# ESP32-C5 register map
Vendor: ESPRESSIF SYSTEMS (SHANGHAI) CO., LTD.; Series: ESP32 C-Series; File version: 1
CPU: RV32IMAC r0p0, little endian, no MPU, no FPU, 0 interrupt priority bits
Address unit: 32 bits
Registers are 32-bit, read-write, reset 0x0 unless marked. A register's access mark holds for its fields unless they carry their own. Offsets are from the block's base; [hi:lo] are bit positions; lines under a group give offsets from that group; {n}, {i} and the like mark numbered series.

## MCPWM0 — Motor Control Pulse Width Modulator (MCPWM) Peripheral
Base 0x60014000
0x00 CLK_CFG — PWM clock prescaler register.
  [7:0] CLK_PRESCALE — Configures the prescaler value of clock, so that the period of PWM_clk = 6.25ns * (PWM_CLK_PRESCALE + 1).
{0x4+0x10*i} TIMER{i} (i=0..2) group — Cluster TIMER{i}, containing TIMER?_CFG0, TIMER?_CFG1, TIMER?_SYNC, TIMER?_STATUS
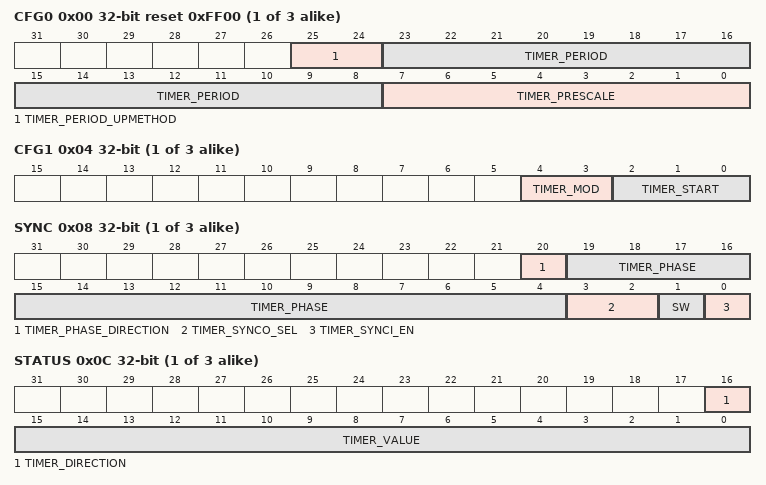
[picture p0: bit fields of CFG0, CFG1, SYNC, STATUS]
  0x00 CFG0 reset 0xFF00 — PWM TIMERx period and update method configuration register.
    [25:24] TIMER_PERIOD_UPMETHOD — Configures the update method for active register of PWM timer%s period.\\0: Immediate\\1: TEZ\\2: Sync\\3: TEZ or sync\\TEZ here and below means timer equal zero event
    [23:8] TIMER_PERIOD — Configures the period shadow of PWM timer%s
    [7:0] TIMER_PRESCALE — Configures the prescaler value of timer%s, so that the period of PT0_clk = Period of PWM_clk * (PWM_TIMER%s_PRESCALE + 1)
  0x04 CFG1 — PWM TIMERx working mode and start/stop control configuration register.
    [4:3] TIMER_MOD — Configures the working mode of PWM timer%s.\\0: Freeze\\1: Increase mode\\2: Decrease mode\\3: Up-down mode
    [2:0] TIMER_START — Configures whether or not to start/stop PWM timer%s.\\0: If PWM timer%s starts, then stops at TEZ\\1: If timer%s starts, then stops at TEP\\2: PWM timer%s starts and runs on\\3: Timer%s starts and stops at the next TEZ\\4: Timer0 starts and stops at the next TEP.\\TEP here and below means the event that happens when the timer equals to period
  0x08 SYNC — PWM TIMERx sync function configuration register.
    [20] TIMER_PHASE_DIRECTION — Configures the PWM timer%s's direction when timer%s mode is up-down mode.\\0: Increase\\1: Decrease
    [19:4] TIMER_PHASE — Configures the phase for timer%s reload on sync event.
    [3:2] TIMER_SYNCO_SEL — Configures the selection of PWM timer%s sync_out.\\0: Sync_in\\1: TEZ\\2: TEP\\3: Invalid, sync_out selects noting
    [1] SW — Configures the generation of software sync. Toggling this bit will trigger a software sync.
    [0] TIMER_SYNCI_EN — Configures whether or not to enable timer%s reloading with phase on sync input event is enabled.\\0: Disable\\1: Enable
  0x0C STATUS ro — PWM TIMERx status register.
    [16] TIMER_DIRECTION — Represents current PWM timer%s counter direction.\\0: Increment\\1: Decrement
    [15:0] TIMER_VALUE — Represents current PWM timer%s counter value.
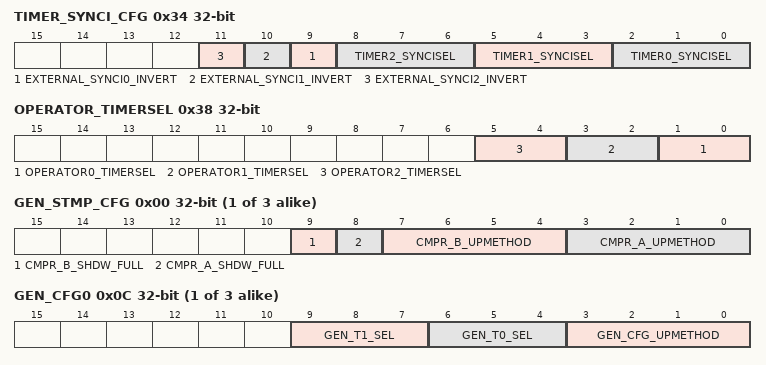
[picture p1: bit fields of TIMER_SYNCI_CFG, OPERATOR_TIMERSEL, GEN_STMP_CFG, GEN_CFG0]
0x34 TIMER_SYNCI_CFG — Synchronization input selection register for PWM timers.
  [n+9] EXTERNAL_SYNCI{n}_INVERT (n=0..2) — Configures whether or not to invert SYNC{n} from GPIO matrix.\\0: Not invert\\1: Invert
  [3n+2:3n] TIMER{n}_SYNCISEL (n=0..2) — Configures the selection of sync input for PWM timer{n}.\\1: PWM timer0 sync_out\\2: PWM timer1 sync_out\\3: PWM timer2 sync_out\\4: SYNC0 from GPIO matrix\\5: SYNC1 from GPIO matrix\\6: SYNC2 from GPIO matrix\\Other values: No sync input selected
0x38 OPERATOR_TIMERSEL — PWM operator's timer select register
  [2n+1:2n] OPERATOR{n}_TIMERSEL (n=0..2) — Configures which PWM timer will be the timing reference for PWM operator{n}.\\0: Timer0\\1: Timer1\\2: Timer2\\3: Invalid, will select timer2
{0x3C+0x38*i} CH{i} (i=0..2) group — Cluster CH{i}, containing GEN?_STMP_CFG, GEN?_TSTMP_A, GEN?_TSTMP_B, GEN?_CFG0, GEN?_FORCE, GEN?_A, GEN?_B, DT?_CFG, DT?_FED_CFG, DT?_RED_CFG, CARRIER?_CFG, FH?_CFG0, FH?_CFG1, FH?_STATUS
  0x00 GEN_STMP_CFG — Transfer status and update method for time stamp registers A and B
    [9] CMPR_B_SHDW_FULL — Represents whether or not generator%s time stamp B's shadow reg is transferred.\\0: B's active reg has been updated with shadow register latest value.\\1: B's shadow reg is filled and waiting to be transferred to B's active reg
    [8] CMPR_A_SHDW_FULL — Represents whether or not generator%s time stamp A's shadow reg is transferred.\\0: A's active reg has been updated with shadow register latest value.\\1: A's shadow reg is filled and waiting to be transferred to A's active reg
    [7:4] CMPR_B_UPMETHOD — Configures the update method for PWM generator %s time stamp B's active register.\\0: Immediately\\Bit0 is set to 1: TEZ\\Bit1 is set to 1: TEP\\Bit2 is set to 1: Sync\\Bit3 is set to 1: Disable the update
    [3:0] CMPR_A_UPMETHOD — Configures the update method for PWM generator %s time stamp A's active register.\\0: Immediately\\Bit0 is set to 1: TEZ\\Bit1 is set to 1: TEP\\Bit2 is set to 1: Sync\\Bit3 is set to 1: Disable the update
  0x04 GEN_TSTMP_A — Shadow register for register A.
    [15:0] CMPR_A — Configures the value of PWM generator %s time stamp A's shadow register.
  0x08 GEN_TSTMP_B — Shadow register for register B.
    [15:0] CMPR_B — Configures the value of PWM generator %s time stamp B's shadow register.
  0x0C GEN_CFG0 — Generator0 fault event T0 and T1 configuration register
    [9:7] GEN_T1_SEL — Configures source selection for PWM generator %s event_t1, take effect immediately.\\0: fault_event0\\1: fault_event1\\2: fault_event2\\3: sync_taken\\4: Invalid, Select nothing
    [6:4] GEN_T0_SEL — Configures source selection for PWM generator %s event_t0, take effect immediately.\\0: fault_event0\\1: fault_event1\\2: fault_event2\\3: sync_taken\\4: Invalid, Select nothing
    [3:0] GEN_CFG_UPMETHOD — Configures update method for PWM generator %s's active register.\\0: Immediately\\Bit0 is set to 1: TEZ\\Bit1 is set to 1: TEP\\Bit2 is set to 1: Sync\\Bit3 is set to 1: Disable the update
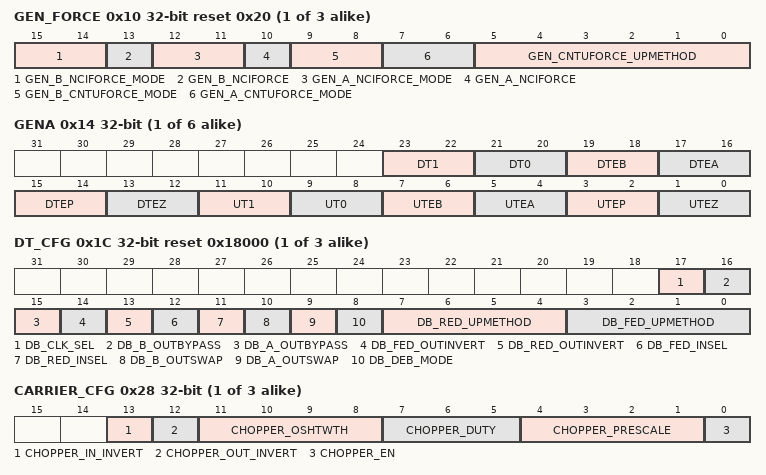
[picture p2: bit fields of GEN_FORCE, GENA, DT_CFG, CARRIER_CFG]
  0x10 GEN_FORCE reset 0x20 — Permissives to force PWMxA and PWMxB outputs by software
    [15:14] GEN_B_NCIFORCE_MODE — Configures non-continuous immediate software force mode for PWM%s B.\\0: Disabled\\1: Low\\2: High\\3: Disabled
    [13] GEN_B_NCIFORCE — Configures the generation of non-continuous immediate software-force event for PWM%s B, a toggle will trigger a force event.
    [12:11] GEN_A_NCIFORCE_MODE — Configures non-continuous immediate software force mode for PWM%s A.\\0: Disabled\\1: Low\\2: High\\3: Disabled
    [10] GEN_A_NCIFORCE — Configures the generation of non-continuous immediate software-force event for PWM%s A, a toggle will trigger a force event.
    [9:8] GEN_B_CNTUFORCE_MODE — Configures continuous software force mode for PWM%s B.\\0: Disabled\\1: Low\\2: High\\3: Disabled
    [7:6] GEN_A_CNTUFORCE_MODE — Configures continuous software force mode for PWM%s A.\\0: Disabled\\1: Low\\2: High\\3: Disabled
    [5:0] GEN_CNTUFORCE_UPMETHOD — Configures update method for continuous software force of PWM generator%s.\\0: Immediately\\Bit0 is set to 1: TEZ\\Bit1 is set to 1: TEP\\Bit2 is set to 1: TEA\\Bit3 is set to 1: TEB\\Bit4 is set to 1: Sync\\Bit5 is set to 1: Disable update. TEA/B here and below means an event generated when the timer's value equals to that of register A/B.
  0x14 GEN{x} (x=A,B; step 0x4) — Actions triggered by events on PWMx{x}
    [23:22] DT1 — Configures action on PWM%s A triggered by event_t1 when timer decreasing.\\0: No change\\1: Low\\2: High\\3: Toggle
    [21:20] DT0 — Configures action on PWM%s A triggered by event_t0 when timer decreasing.\\0: No change\\1: Low\\2: High\\3: Toggle
    [19:18] DTEB — Configures action on PWM%s A triggered by event TEB when timer decreasing.\\0: No change\\1: Low\\2: High\\3: Toggle
    [17:16] DTEA — Configures action on PWM%s A triggered by event TEA when timer decreasing.\\0: No change\\1: Low\\2: High\\3: Toggle
    [15:14] DTEP — Configures action on PWM%s A triggered by event TEP when timer decreasing.\\0: No change\\1: Low\\2: High\\3: Toggle
    [13:12] DTEZ — Configures action on PWM%s A triggered by event TEZ when timer decreasing.\\0: No change\\1: Low\\2: High\\3: Toggle
    [11:10] UT1 — Configures action on PWM%s A triggered by event_t1 when timer increasing.\\0: No change\\1: Low\\2: High\\3: Toggle
    [9:8] UT0 — Configures action on PWM%s A triggered by event_t0 when timer increasing.\\0: No change\\1: Low\\2: High\\3: Toggle
    [7:6] UTEB — Configures action on PWM%s A triggered by event TEB when timer increasing.\\0: No change\\1: Low\\2: High\\3: Toggle
    [5:4] UTEA — Configures action on PWM%s A triggered by event TEA when timer increasing.\\0: No change\\1: Low\\2: High\\3: Toggle
    [3:2] UTEP — Configures action on PWM%s A triggered by event TEP when timer increasing.\\0: No change\\1: Low\\2: High\\3: Toggle
    [1:0] UTEZ — Configures action on PWM%s A triggered by event TEZ when timer increasing.\\0: No change\\1: Low\\2: High\\3: Toggle
  0x1C DT_CFG reset 0x18000 — Dead time type selection and configuration
    [17] DB_CLK_SEL — Configures dead time generator %s clock selection.\\0: PWM_clk\\1: PT_clk
    [16] DB_B_OUTBYPASS — Configures S0 in table.
    [15] DB_A_OUTBYPASS — Configures S1 in table.
    [14] DB_FED_OUTINVERT — Configures S3 in table.
    [13] DB_RED_OUTINVERT — Configures S2 in table.
    [12] DB_FED_INSEL — Configures S5 in table.
    [11] DB_RED_INSEL — Configures S4 in table.
    [10] DB_B_OUTSWAP — Configures S7 in table.
    [9] DB_A_OUTSWAP — Configures S6 in table.
    [8] DB_DEB_MODE — Configures S8 in table, dual-edge B mode.\\0: fed/red take effect on different path separately\\1: fed/red take effect on B path, A out is in bypass or dulpB mode
    [7:4] DB_RED_UPMETHOD — Configures update method for RED (rising edge delay) active register.\\0: Immediate\\Bit0 is set to 1: TEZ\\Bit1 is set to 1: TEP\\Bit2 is set to 1: Sync\\Bit3 is set to 1: Disable the update
    [3:0] DB_FED_UPMETHOD — Configures update method for FED (Falling edge delay) active register.\\0: Immediate\\Bit0 is set to 1: TEZ\\Bit1 is set to 1: TEP\\Bit2 is set to 1: Sync\\Bit3 is set to 1: Disable the update
  0x20 DT_FED_CFG — Shadow register for falling edge delay (FED).
    [15:0] DB_FED — Configures shadow register for FED.
  0x24 DT_RED_CFG — Shadow register for rising edge delay (RED).
    [15:0] DB_RED — Configures shadow register for RED.
  0x28 CARRIER_CFG — Carrier enable and configuratoin
    [13] CHOPPER_IN_INVERT — Configures whether or not to invert the input of PWM%s A and PWM%s B for this submodule.\\0: Normal\\1: Invert
    [12] CHOPPER_OUT_INVERT — Configures whether or not to invert the output of PWM%s A and PWM%s B for this submodule.\\0: Normal\\1: Invert
    [11:8] CHOPPER_OSHTWTH — Configures width of the first pulse. Measurement unit: Periods of the carrier.
    [7:5] CHOPPER_DUTY — Configures carrier duty. Duty = PWM_CARRIER%s_DUTY / 8
    [4:1] CHOPPER_PRESCALE — Configures the prescale value of PWM carrier%s clock (PC_clk), so that period of PC_clk = period of PWM_clk * (PWM_CARRIER%s_PRESCALE + 1)
    [0] CHOPPER_EN — Configures whether or not to enable carrier%s.\\0: Bypassed\\1: Enabled
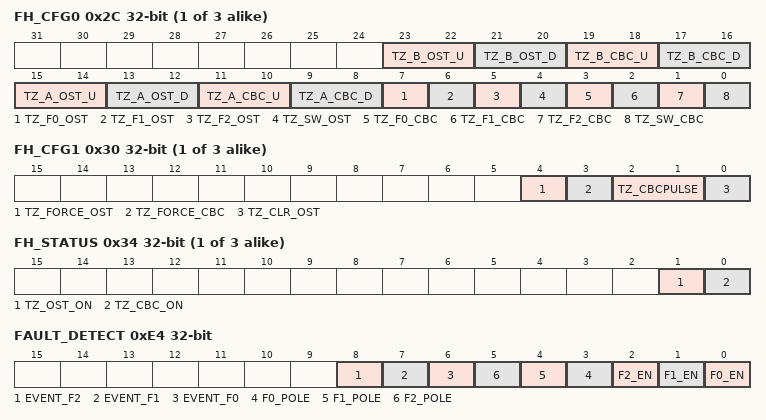
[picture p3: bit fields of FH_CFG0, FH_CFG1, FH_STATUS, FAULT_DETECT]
  0x2C FH_CFG0 — Actions on PWM0A and PWM0B trip events
    [23:22] TZ_B_OST_U — Configures one-shot mode action on PWM%s B when fault event occurs and timer is increasing.\\0: Do nothing\\1: Force low\\2: Force high\\3: Toggle
    [21:20] TZ_B_OST_D — Configures one-shot mode action on PWM%s B when fault event occurs and timer is decreasing.\\0: Do nothing\\1: Force low\\2: Force high\\3: Toggle
    [19:18] TZ_B_CBC_U — Configures cycle-by-cycle mode action on PWM%s B when fault event occurs and timer is increasing.\\0: Do nothing\\1: Force low\\2: Force high\\3: Toggle
    [17:16] TZ_B_CBC_D — Configures cycle-by-cycle mode action on PWM%s B when fault event occurs and timer is decreasing.\\0: Do nothing\\1: Force low\\2: Force high\\3: Toggle
    [15:14] TZ_A_OST_U — Configures one-shot mode action on PWM%s A when fault event occurs and timer is increasing.\\0: Do nothing\\1: Force low\\2: Force high\\3: Toggle
    [13:12] TZ_A_OST_D — Configures one-shot mode action on PWM%s A when fault event occurs and timer is decreasing.\\0: Do nothing\\1: Force low\\2: Force high\\3: Toggle
    [11:10] TZ_A_CBC_U — Configures cycle-by-cycle mode action on PWM%s A when fault event occurs and timer is increasing.\\0: Do nothing\\1: Force low\\2: Force high\\3: Toggle
    [9:8] TZ_A_CBC_D — Configures cycle-by-cycle mode action on PWM%s A when fault event occurs and timer is decreasing.\\0: Do nothing\\1: Force low\\2: Force high\\3: Toggle
    [7] TZ_F0_OST — Configures whether or not event_f0 will trigger one-shot mode action.\\0: Disable\\1: Enable
    [6] TZ_F1_OST — Configures whether or not event_f1 will trigger one-shot mode action.\\0: Disable\\1: Enable
    [5] TZ_F2_OST — Configures whether or not event_f2 will trigger one-shot mode action.\\0: Disable\\1: Enable
    [4] TZ_SW_OST — Configures whether or not to enable software force one-shot mode action.\\0: Disable\\1: Enable
    [3] TZ_F0_CBC — Configures whether or not event_f0 will trigger cycle-by-cycle mode action.\\0: Disable\\1: Enable
    [2] TZ_F1_CBC — Configures whether or not event_f1 will trigger cycle-by-cycle mode action.\\0: Disable\\1: Enable
    [1] TZ_F2_CBC — Configures whether or not event_f2 will trigger cycle-by-cycle mode action.\\0: Disable\\1: Enable
    [0] TZ_SW_CBC — Configures whether or not to enable software force cycle-by-cycle mode action.\\0: Disable\\1: Enable
  0x30 FH_CFG1 — Software triggers for fault handler actions
    [4] TZ_FORCE_OST — Configures the generation of software one-shot mode action. A toggle (software negate its value) triggers a one-shot mode action.
    [3] TZ_FORCE_CBC — Configures the generation of software cycle-by-cycle mode action. A toggle (software negate its value) triggers a cycle-by-cycle mode action.
    [2:1] TZ_CBCPULSE — Configures the refresh moment selection of cycle-by-cycle mode action.\\0: Select nothing, will not refresh\\Bit0 is set to 1: TEZ\\Bit1 is set to 1: TEP
    [0] TZ_CLR_OST — Configures the generation of software one-shot mode action clear. A toggle (software negate its value) triggers a clear for on going one-shot mode action.
  0x34 FH_STATUS ro — Status of fault events.
    [1] TZ_OST_ON — Represents whether or not an one-shot mode action is on going.\\0:No action\\1: On going
    [0] TZ_CBC_ON — Represents whether or not an cycle-by-cycle mode action is on going.\\0:No action\\1: On going
0xE4 FAULT_DETECT access per field — Fault detection configuration and status register
  [8] EVENT_F2 ro — Represents whether or not an event_f2 is on going.\\0: No action\\1: On going
  [7] EVENT_F1 ro — Represents whether or not an event_f1 is on going.\\0: No action\\1: On going
  [6] EVENT_F0 ro — Represents whether or not an event_f0 is on going.\\0: No action\\1: On going
  [n+3] F{n}_POLE (n=0..2) rw — Configures the polarity of the fault trigger on FAULT{n} source from GPIO matrix.\0: Level low\1: Level high
  [n] F{n}_EN (n=0..2) rw — Configures whether or not to enable event_f{n} generation.\\0: Disable\\1: Enable
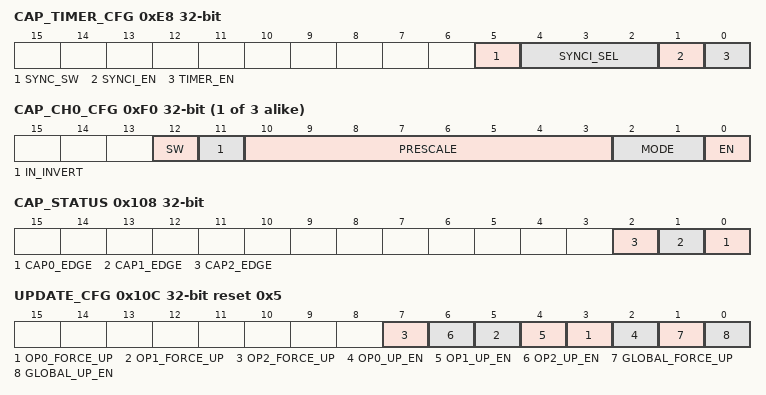
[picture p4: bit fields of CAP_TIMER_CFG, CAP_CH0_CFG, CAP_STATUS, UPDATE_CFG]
0xE8 CAP_TIMER_CFG access per field — Capture timer configuration register
  [5] SYNC_SW wo — Configures the generation of a capture timer sync when reg_cap_synci_en is 1.\\0: Invalid, No effect\\1: Trigger a capture timer sync, capture timer is loaded with value in phase register
  [4:2] SYNCI_SEL rw — Configures the selection of capture module sync input.\\0: None\\1: Timer0 sync_out\\2: Timer1 sync_out\\3: Timer2 sync_out\\4: SYNC0 from GPIO matrix\\5: SYNC1 from GPIO matrix\\6: SYNC2 from GPIO matrix\\7: None
  [1] SYNCI_EN rw — Configures whether or not to enable capture timer sync.\\0: Disable\\1: Enable
  [0] TIMER_EN rw — Configures whether or not to enable capture timer increment.\\0: Disable\\1: Enable
0xEC CAP_TIMER_PHASE — Capture timer sync phase register
  [31:0] PHASE — Configures phase value for capture timer sync operation.
{0xF0+4i} CAP_CH{i}_CFG (i=0..2) access per field — Capture channel {i} configuration and enable
  [12] SW wo — Configures the generation of software capture.\\0: Invalid, No effect\\1: Trigger a software forced capture on channel %s
  [11] IN_INVERT rw — Configures whether or not to invert CAP%s from GPIO matrix before prescale.\\0: Normal\\1: Invert
  [10:3] PRESCALE rw — Configures prescale value on possitive edge of CAP%s. Prescale value = PWM_CAP%s_PRESCALE + 1
  [2:1] MODE rw — Describes which edges to trigger a capture event
    0=None (Capture nothing); 1=FallingEdge (Capture falling edges); 2=RisingEdge (Capture rising edges); 3=AnyEdge (Capture any edges)
  [0] EN rw — Configures whether or not to enable capture on channel %s.\\0: Disable\\1: Enable
{0xFC+4i} CAP_CH{i} (i=0..2) ro — Value of last capture on channel {i}
  [31:0] VALUE
0x108 CAP_STATUS ro — Last capture trigger edge information register
  [n] CAP{n}_EDGE (n=0..2) — Describes the last captured edge on channel{n}.
    0=Rising edge; 1=Falling edge
0x10C UPDATE_CFG reset 0x5 — Generator Update configuration register
  [2n+3] OP{n}_FORCE_UP (n=0..2) — A toggle (software invert its value) will trigger a forced update of active registers in PWM operator {n}
  [2n+2] OP{n}_UP_EN (n=0..2) — Configures whether or not to enable update of active registers in PWM operator{n}. Valid only when PWM_GLOBAL_UP_EN is set to 1.\\0: Disable\\1: Enable
  [1] GLOBAL_FORCE_UP — Configures the generation of global forced update for all active registers in MCPWM module. A toggle (software invert its value) will trigger a global forced update. Valid only when MCPWM_GLOBAL_UP_EN and MCPWM_OP0/1/2_UP_EN are both set to 1.
  [0] GLOBAL_UP_EN — Configures whether or not to enable global update for all active registers in MCPWM module.\\0: Disable\\1: Enable
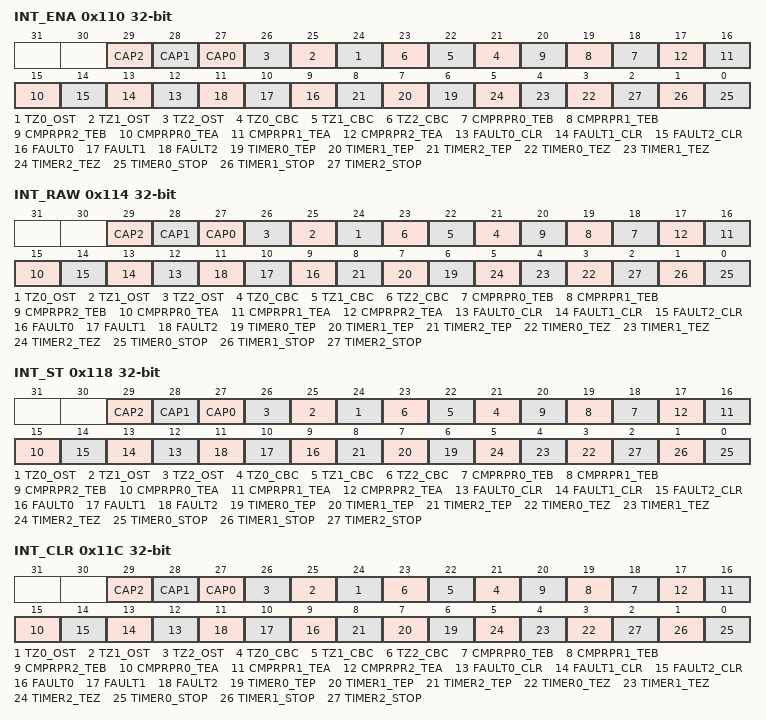
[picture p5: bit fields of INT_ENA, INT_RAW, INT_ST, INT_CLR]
0x110 INT_ENA — Interrupt enable register
  [n+27] CAP{n} (n=0..2) — The interrupt enable bit for the capture{n} event.
  [n+24] TZ{n}_OST (n=0..2) — The interrupt enable bit for the fault handler{n} one-shot mode action.
  [n+21] TZ{n}_CBC (n=0..2) — The interrupt enable bit for the fault handler{n} cycle-by-cycle mode action.
  [18] CMPR{x}_TEB (x=PR0,PR1,PR2; step 1) — The interrupt enable bit for the operator{x} compare B event.
  [15] CMPR{x}_TEA (x=PR0,PR1,PR2; step 1) — The interrupt enable bit for the operator{x} compare A event.
  [n+12] FAULT{n}_CLR (n=0..2) — The interrupt enable bit for the fault{n} clear event.
  [n+9] FAULT{n} (n=0..2) — The interrupt enable bit for the fault{n} event.
  [n+6] TIMER{n}_TEP (n=0..2) — The interrupt enable bit for the timer{n} period event.
  [n+3] TIMER{n}_TEZ (n=0..2) — The interrupt enable bit for the timer{n} zero event.
  [n] TIMER{n}_STOP (n=0..2) — The interrupt enable bit for the timer{n} stop event.
0x114 INT_RAW — Interrupt raw status register
  [n+27] CAP{n} (n=0..2) — The interrupt raw bit for the capture{n} event.
  [n+24] TZ{n}_OST (n=0..2) — The interrupt raw bit for the fault handler{n} one-shot mode action.
  [n+21] TZ{n}_CBC (n=0..2) — The interrupt raw bit for the fault handler{n} cycle-by-cycle mode action.
  [18] CMPR{x}_TEB (x=PR0,PR1,PR2; step 1) — The interrupt raw bit for the operator{x} compare B event.
  [15] CMPR{x}_TEA (x=PR0,PR1,PR2; step 1) — The interrupt raw bit for the operator{x} compare A event.
  [n+12] FAULT{n}_CLR (n=0..2) — The interrupt raw bit for the fault{n} clear event.
  [n+9] FAULT{n} (n=0..2) — The interrupt raw bit for the fault{n} event.
  [n+6] TIMER{n}_TEP (n=0..2) — The interrupt raw bit for the timer{n} period event.
  [n+3] TIMER{n}_TEZ (n=0..2) — The interrupt raw bit for the timer{n} zero event.
  [n] TIMER{n}_STOP (n=0..2) — The interrupt raw bit for the timer{n} stop event.
0x118 INT_ST ro — Interrupt masked status register
  [n+27] CAP{n} (n=0..2) — The interrupt status bit for the capture{n} event.
  [n+24] TZ{n}_OST (n=0..2) — The interrupt status bit for the fault handler{n} one-shot mode action.
  [n+21] TZ{n}_CBC (n=0..2) — The interrupt status bit for the fault handler{n} cycle-by-cycle mode action.
  [18] CMPR{x}_TEB (x=PR0,PR1,PR2; step 1) — The interrupt status bit for the operator{x} compare B event.
  [15] CMPR{x}_TEA (x=PR0,PR1,PR2; step 1) — The interrupt status bit for the operator{x} compare A event.
  [n+12] FAULT{n}_CLR (n=0..2) — The interrupt status bit for the fault{n} clear event.
  [n+9] FAULT{n} (n=0..2) — The interrupt status bit for the fault{n} event.
  [n+6] TIMER{n}_TEP (n=0..2) — The interrupt status bit for the timer{n} period event.
  [n+3] TIMER{n}_TEZ (n=0..2) — The interrupt status bit for the timer{n} zero event.
  [n] TIMER{n}_STOP (n=0..2) — The interrupt status bit for the timer{n} stop event.
0x11C INT_CLR wo — Interrupt clear register
  [n+27] CAP{n} (n=0..2) write-1-clears — The interrupt clear bit for the capture{n} event.
  [n+24] TZ{n}_OST (n=0..2) write-1-clears — The interrupt clear bit for the fault handler{n} one-shot mode action.
  [n+21] TZ{n}_CBC (n=0..2) write-1-clears — The interrupt clear bit for the fault handler{n} cycle-by-cycle mode action.
  [18] CMPR{x}_TEB (x=PR0,PR1,PR2; step 1) write-1-clears — The interrupt clear bit for the operator{x} compare B event.
  [15] CMPR{x}_TEA (x=PR0,PR1,PR2; step 1) write-1-clears — The interrupt clear bit for the operator{x} compare A event.
  [n+12] FAULT{n}_CLR (n=0..2) write-1-clears — The interrupt clear bit for the fault{n} clear event.
  [n+9] FAULT{n} (n=0..2) write-1-clears — The interrupt clear bit for the fault{n} event.
  [n+6] TIMER{n}_TEP (n=0..2) write-1-clears — The interrupt clear bit for the timer{n} period event.
  [n+3] TIMER{n}_TEZ (n=0..2) write-1-clears — The interrupt clear bit for the timer{n} zero event.
  [n] TIMER{n}_STOP (n=0..2) write-1-clears — The interrupt clear bit for the timer{n} stop event.
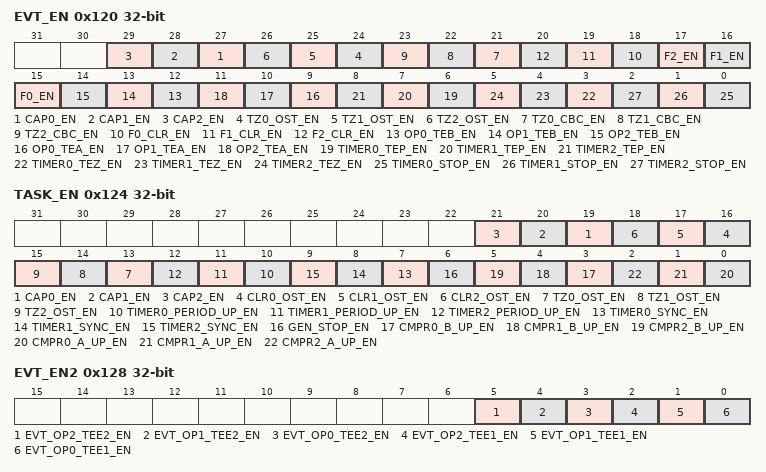
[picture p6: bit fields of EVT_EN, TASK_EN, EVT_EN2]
0x120 EVT_EN — Event enable register
  [n+27] CAP{n}_EN (n=0..2) — Configures whether or not to enable capture{n} event generate.\\0: Disable\\1: Enable
  [n+24] TZ{n}_OST_EN (n=0..2) — Configures whether or not to enable one-shot trip{n} event generate.\\0: Disable\\1: Enable
  [n+21] TZ{n}_CBC_EN (n=0..2) — Configures whether or not to enable cycle-by-cycle trip{n} event generate.\\0: Disable\\1: Enable
  [n+18] F{n}_CLR_EN (n=0..2) — Configures whether or not to enable fault{n} clear event generate.\\0: Disable\\1: Enable
  [n+15] F{n}_EN (n=0..2) — Configures whether or not to enable fault{n} event generate.\\0: Disable\\1: Enable
  [n+12] OP{n}_TEB_EN (n=0..2) — Configures whether or not to enable PWM generator{n} timer equal b event generate.\\0: Disable\\1: Enable
  [n+9] OP{n}_TEA_EN (n=0..2) — Configures whether or not to enable PWM generator{n} timer equal a event generate.\\0: Disable\\1: Enable
  [n+6] TIMER{n}_TEP_EN (n=0..2) — Configures whether or not to enable timer{n} equal period event generate.\\0: Disable\\1: Enable
  [n+3] TIMER{n}_TEZ_EN (n=0..2) — Configures whether or not to enable timer{n} equal zero event generate.\\0: Disable\\1: Enable
  [n] TIMER{n}_STOP_EN (n=0..2) — Configures whether or not to enable timer{n} stop event generate.\\0: Disable\\1: Enable
0x124 TASK_EN — Task enable register
  [n+19] CAP{n}_EN (n=0..2) — Configures whether or not to enable capture{n} task receive.\\0: Disable\\1: Enable
  [n+16] CLR{n}_OST_EN (n=0..2) — Configures whether or not to enable one shot trip{n} clear task receive.\\0: Disable\\1: Enable
  [n+13] TZ{n}_OST_EN (n=0..2) — Configures whether or not to enable one shot trip{n} task receive.\\0: Disable\\1: Enable
  [n+10] TIMER{n}_PERIOD_UP_EN (n=0..2) — Configures whether or not to enable timer{n} period update task receive.\\0: Disable\\1: Enable
  [n+7] TIMER{n}_SYNC_EN (n=0..2) — Configures whether or not to enable timer{n} sync task receive.\\0: Disable\\1: Enable
  [6] GEN_STOP_EN — Configures whether or not to enable all PWM generate stop task receive.\\0: Disable\\1: Enable
  [n+3] CMPR{n}_B_UP_EN (n=0..2) — Configures whether or not to enable PWM generator{n} timer stamp B's shadow register update task receive.\\0: Disable\\1: Enable
  [n] CMPR{n}_A_UP_EN (n=0..2) — Configures whether or not to enable PWM generator{n} timer stamp A's shadow register update task receive.\\0: Disable\\1: Enable
0x128 EVT_EN2 — Event enable register2
  [5] EVT_OP2_TEE2_EN — Configures whether or not to enable PWM generator2 timer equal OP2_TSTMP_E2_REG event generate.\\0: Disable\\1: Enable
  [4] EVT_OP1_TEE2_EN — Configures whether or not to enable PWM generator1 timer equal OP1_TSTMP_E2_REG event generate.\\0: Disable\\1: Enable
  [3] EVT_OP0_TEE2_EN — Configures whether or not to enable PWM generator0 timer equal OP0_TSTMP_E2_REG event generate.\\0: Disable\\1: Enable
  [2] EVT_OP2_TEE1_EN — Configures whether or not to enable PWM generator2 timer equal OP2_TSTMP_E1_REG event generate.\\0: Disable\\1: Enable
  [1] EVT_OP1_TEE1_EN — Configures whether or not to enable PWM generator1 timer equal OP1_TSTMP_E1_REG event generate.\\0: Disable\\1: Enable
  [0] EVT_OP0_TEE1_EN — Configures whether or not to enable PWM generator0 timer equal OP0_TSTMP_E1_REG event generate.\\0: Disable\\1: Enable
{0x12C+8i} OP{i}_TSTMP_E1 (i=0..2) — Generator{i} timer stamp E1 value register
  [15:0] OP_TSTMP_E1 — Configures generator%s timer stamp E1 value register
{0x130+8i} OP{i}_TSTMP_E2 (i=0..2) — Generator{i} timer stamp E2 value register
  [15:0] OP_TSTMP_E2 — Configures generator%s timer stamp E2 value register
0x144 CLK — Global configuration register
  [0] EN — Configures whether or not to open register clock gate.\\0: Open the clock gate only when application writes registers\\1: Force open the clock gate for register
0x148 VERSION
